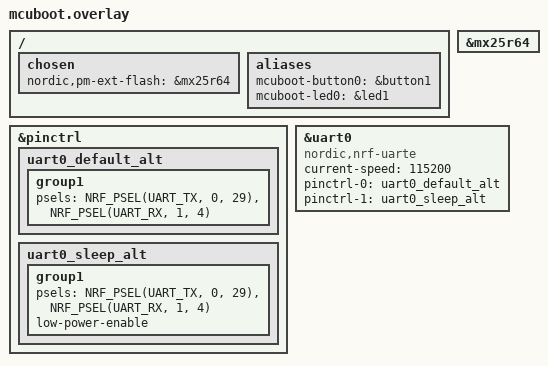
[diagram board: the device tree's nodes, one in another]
/* STEP 2.2 - Add external flash to MCUboot */
&mx25r64 {
	status = "okay";
};

/ {
	chosen {
		nordic,pm-ext-flash = &mx25r64;
	};
};
/ {
  aliases {
		mcuboot-button0 = &button1;
		mcuboot-led0 = &led1;
  };
};
&pinctrl {
    uart0_default_alt: uart0_default_alt {
      group1 {
         psels = <NRF_PSEL(UART_TX, 0, 29)>,
				<NRF_PSEL(UART_RX, 1, 4)>;
      };
   };
   uart0_sleep_alt: uart0_sleep_alt {
      group1 {
         psels = <NRF_PSEL(UART_TX, 0, 29)>,
			     <NRF_PSEL(UART_RX, 1, 4)>;
         low-power-enable;
      };
   };
};

&uart0 {
   status = "okay";
   compatible = "nordic,nrf-uarte";
   current-speed = <115200>;
   pinctrl-0 = <&uart0_default_alt>;
   pinctrl-1 = <&uart0_sleep_alt>;
   pinctrl-names = "default", "sleep";
};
